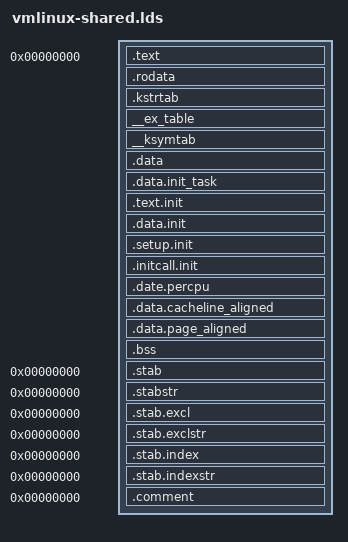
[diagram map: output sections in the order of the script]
/* ld script to make s390 Linux kernel
 * Written by Martin Schwidefsky (schwidefsky@de.ibm.com)
 */
OUTPUT_FORMAT("elf32-s390", "elf32-s390", "elf32-s390")
OUTPUT_ARCH(s390)
ENTRY(_start)
jiffies = jiffies_64 + 4;
SECTIONS
{
  . = 0x00000000;
  _text = .;			/* Text and read-only data */
  .text : {
	*(.text)
	*(.fixup)
	*(.gnu.warning)
	} = 0x0700

  _etext = .;			/* End of text section */

  .rodata : { *(.rodata) }
  .kstrtab : { *(.kstrtab) }

  . = ALIGN(16);		/* Exception table */
  __start___ex_table = .;
  __ex_table : { *(__ex_table) }
  __stop___ex_table = .;

  __start___ksymtab = .;	/* Kernel symbol table */
  __ksymtab : { *(__ksymtab) }
  __stop___ksymtab = .;

  . = ALIGN(1048576);		/* VM shared segments are 1MB aligned */

  _eshared = .;			/* End of shareable data */

  .data : {			/* Data */
	*(.data)
	CONSTRUCTORS
	}

  _edata = .;			/* End of data section */

  . = ALIGN(8192);		/* init_task */
  .data.init_task : { *(.data.init_task) }

  . = ALIGN(4096);		/* Init code and data */
  __init_begin = .;
  .text.init : { *(.text.init) }
  .data.init : { *(.data.init) }
  . = ALIGN(256);
  __setup_start = .;
  .setup.init : { *(.setup.init) }
  __setup_end = .;
  __initcall_start = .;
  .initcall.init : {
	*(.initcall1.init) 
	*(.initcall2.init) 
	*(.initcall3.init) 
	*(.initcall4.init) 
	*(.initcall5.init) 
	*(.initcall6.init) 
	*(.initcall7.init)
  }
  __initcall_end = .;
  . = ALIGN(256);
  __per_cpu_start = .;
  .date.percpu  : { *(.data.percpu) }
  __per_cpu_end = .;
  . = ALIGN(4096);
  __init_end = .;

  . = ALIGN(32);
  .data.cacheline_aligned : { *(.data.cacheline_aligned) }

  . = ALIGN(4096);
  .data.page_aligned : { *(.data.idt) }


  __bss_start = .;		/* BSS */
  .bss : {
	*(.bss)
	}
  _end = . ;

  /* Stabs debugging sections.  */
  .stab 0 : { *(.stab) }
  .stabstr 0 : { *(.stabstr) }
  .stab.excl 0 : { *(.stab.excl) }
  .stab.exclstr 0 : { *(.stab.exclstr) }
  .stab.index 0 : { *(.stab.index) }
  .stab.indexstr 0 : { *(.stab.indexstr) }
  .comment 0 : { *(.comment) }
}
